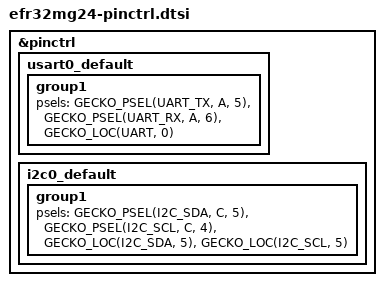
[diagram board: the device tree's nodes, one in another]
/*
 * Copyright (c) 2022 Silicon Labs
 *
 * SPDX-License-Identifier: Apache-2.0
 */

#include <dt-bindings/pinctrl/gecko-pinctrl.h>

&pinctrl {
	/* configuration for uart0 device, default state */
	usart0_default: usart0_default {
		group1 {
			/* configure PA.6 as UART_RX and PA.5 as UART_TX */
			psels = <GECKO_PSEL(UART_TX, A, 5)>,
				<GECKO_PSEL(UART_RX, A, 6)>,
				<GECKO_LOC(UART, 0)>;
		};
	};

	i2c0_default: i2c0_default {
		group1 {
			psels = <GECKO_PSEL(I2C_SDA, C, 5)>,
				<GECKO_PSEL(I2C_SCL, C, 4)>,
				<GECKO_LOC(I2C_SDA, 5)>,
				<GECKO_LOC(I2C_SCL, 5)>;
		};
	};
};
